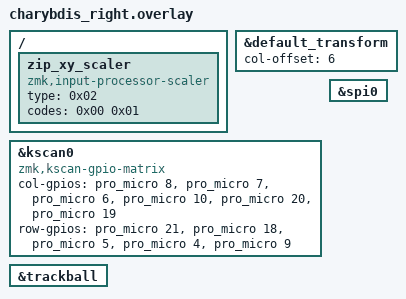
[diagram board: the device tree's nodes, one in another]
#include "charybdis.dtsi"
#include "charybdis_pmw3610.dtsi"

&default_transform {
	col-offset = <6>;
};

&kscan0 {
	compatible = "zmk,kscan-gpio-matrix";
	col-gpios
		= <&pro_micro 8 (GPIO_ACTIVE_HIGH | GPIO_PULL_DOWN)>
		, <&pro_micro 7 (GPIO_ACTIVE_HIGH | GPIO_PULL_DOWN)>
		, <&pro_micro 6 (GPIO_ACTIVE_HIGH | GPIO_PULL_DOWN)>
		, <&pro_micro 10 (GPIO_ACTIVE_HIGH | GPIO_PULL_DOWN)>
		, <&pro_micro 20 (GPIO_ACTIVE_HIGH | GPIO_PULL_DOWN)>
		, <&pro_micro 19 (GPIO_ACTIVE_HIGH | GPIO_PULL_DOWN)>
		;
	row-gpios
                = <&pro_micro 21  GPIO_ACTIVE_HIGH>
                , <&pro_micro 18  GPIO_ACTIVE_HIGH>
                , <&pro_micro 5  GPIO_ACTIVE_HIGH>
                , <&pro_micro 4  GPIO_ACTIVE_HIGH>
                , <&pro_micro 9 GPIO_ACTIVE_HIGH>
                ;
};

&spi0 {
    status = "okay";
};

&trackball {
    status = "okay";
};

/* .keymap ファイルからセンサーを制御するための重要なラベル定義 */
vtrackball: &trackball { };

/ {
  /* スケーラー（一応定義しておきますが、速度調整は keymap 側で行います） */
  zip_xy_scaler: zip_xy_scaler {
    compatible = "zmk,input-processor-scaler";
    #input-processor-cells = <2>;
    type = <0x02>; 
	codes = <0x00 0x01>;
  };
};
